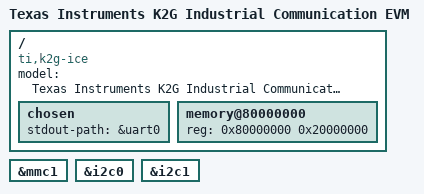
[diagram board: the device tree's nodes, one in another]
/*
 * Device Tree Source for K2G Industrial Communication Engine EVM
 *
 * Copyright (C) 2017 Texas Instruments Incorporated - http://www.ti.com/
 *
 * SPDX-License-Identifier: GPL-2.0+
 */
/dts-v1/;

#include "keystone-k2g.dtsi"

/ {
	compatible = "ti,k2g-ice", "ti,k2g", "ti,keystone";
	model = "Texas Instruments K2G Industrial Communication EVM";

	chosen {
		stdout-path = &uart0;
	};

	memory@80000000 {
		device_type = "memory";
		reg = <0x80000000 0x20000000>;
	};
};

&mmc1 {
	status = "okay";
};

&i2c0 {
	status = "okay";
};

&i2c1 {
	status = "okay";
};
